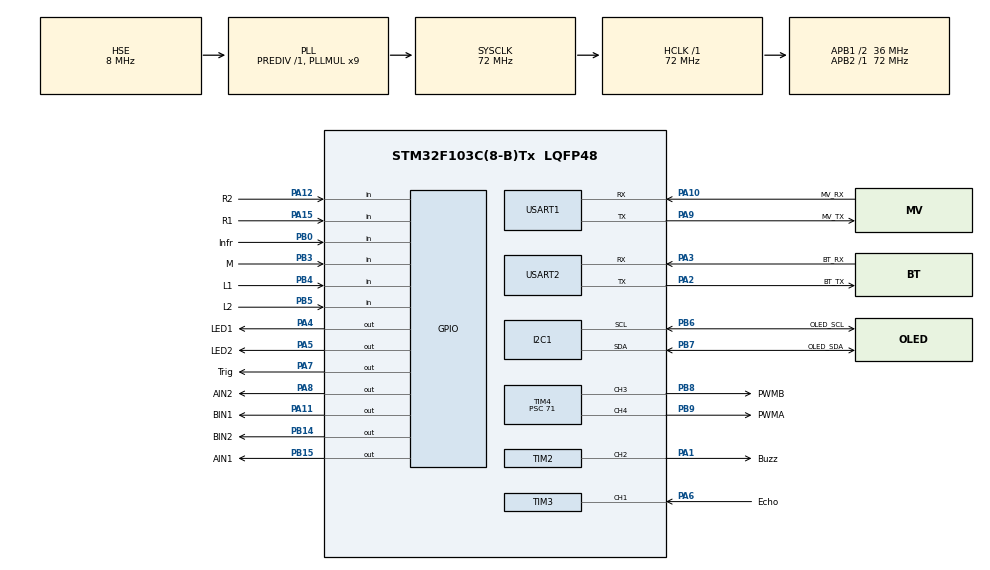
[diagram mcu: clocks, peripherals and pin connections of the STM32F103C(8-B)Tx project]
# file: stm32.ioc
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Dma.Request0=USART2_RX
Dma.Request1=USART2_TX
Dma.USART2_RX.0.Direction=DMA_PERIPH_TO_MEMORY
Dma.USART2_RX.0.Instance=DMA1_Channel6
Dma.USART2_RX.0.MemDataAlignment=DMA_MDATAALIGN_BYTE
Dma.USART2_RX.0.MemInc=DMA_MINC_ENABLE
Dma.USART2_RX.0.Mode=DMA_NORMAL
Dma.USART2_RX.0.PeriphDataAlignment=DMA_PDATAALIGN_BYTE
Dma.USART2_RX.0.PeriphInc=DMA_PINC_DISABLE
Dma.USART2_RX.0.Priority=DMA_PRIORITY_LOW
Dma.USART2_TX.1.Direction=DMA_MEMORY_TO_PERIPH
Dma.USART2_TX.1.Instance=DMA1_Channel7
Dma.USART2_TX.1.MemDataAlignment=DMA_MDATAALIGN_BYTE
Dma.USART2_TX.1.MemInc=DMA_MINC_ENABLE
Dma.USART2_TX.1.Mode=DMA_NORMAL
Dma.USART2_TX.1.PeriphDataAlignment=DMA_PDATAALIGN_BYTE
Dma.USART2_TX.1.PeriphInc=DMA_PINC_DISABLE
Dma.USART2_TX.1.Priority=DMA_PRIORITY_LOW
Mcu.Family=STM32F1
Mcu.Name=STM32F103C(8-B)Tx
Mcu.Package=LQFP48
NVIC.DMA1_Channel6_IRQn=true\:0\:0\:false\:false\:true\:false\:true\:true
NVIC.DMA1_Channel7_IRQn=true\:0\:0\:false\:false\:true\:false\:true\:true
NVIC.PriorityGroup=NVIC_PRIORITYGROUP_4
NVIC.TIM3_IRQn=true\:0\:0\:false\:false\:true\:true\:true\:true
NVIC.USART2_IRQn=true\:0\:0\:false\:false\:true\:false\:true\:true
PA1.GPIO_Label=Buzz
PA1.Signal=S_TIM2_CH2
PA10.GPIO_Label=MV_RX
PA10.Mode=Asynchronous
PA10.Signal=USART1_RX
PA11.GPIO_Label=BIN1
PA11.GPIO_PuPd=GPIO_PULLDOWN
PA11.Signal=GPIO_Output
PA12.GPIO_Label=R2
PA12.GPIO_PuPd=GPIO_PULLDOWN
PA12.Signal=GPIO_Input
PA13.Mode=Serial_Wire
PA13.Signal=SYS_JTMS-SWDIO
PA14.Mode=Serial_Wire
PA14.Signal=SYS_JTCK-SWCLK
PA15.GPIO_Label=R1
PA15.GPIO_PuPd=GPIO_PULLDOWN
PA15.Signal=GPIO_Input
PA2.GPIO_Label=BT_TX
PA2.Mode=Asynchronous
PA2.Signal=USART2_TX
PA3.GPIO_Label=BT_RX
PA3.Mode=Asynchronous
PA3.Signal=USART2_RX
PA4.GPIO_Label=LED1
PA4.GPIO_ModeDefaultOutputPP=GPIO_MODE_OUTPUT_PP
PA4.GPIO_PuPd=GPIO_PULLDOWN
PA4.Signal=GPIO_Output
PA5.GPIO_Label=LED2
PA5.GPIO_PuPd=GPIO_PULLDOWN
PA5.Signal=GPIO_Output
PA6.GPIO_Label=Echo
PA6.Signal=S_TIM3_CH1
PA7.GPIO_Label=Trig
PA7.GPIO_PuPd=GPIO_PULLUP
PA7.GPIO_Speed=GPIO_SPEED_FREQ_HIGH
PA7.Signal=GPIO_Output
PA8.GPIO_Label=AIN2
PA8.GPIO_PuPd=GPIO_PULLDOWN
PA8.Signal=GPIO_Output
PA9.GPIO_Label=MV_TX
PA9.Mode=Asynchronous
PA9.Signal=USART1_TX
PB0.GPIO_Label=Infr
PB0.GPIO_PuPd=GPIO_PULLUP
PB0.Signal=GPIO_Input
PB14.GPIO_Label=BIN2
PB14.GPIO_PuPd=GPIO_PULLDOWN
PB14.Signal=GPIO_Output
PB15.GPIO_Label=AIN1
PB15.GPIO_PuPd=GPIO_PULLDOWN
PB15.Signal=GPIO_Output
PB3.GPIO_Label=M
PB3.GPIO_PuPd=GPIO_PULLDOWN
PB3.Signal=GPIO_Input
PB4.GPIO_Label=L1
PB4.GPIO_PuPd=GPIO_PULLDOWN
PB4.Signal=GPIO_Input
PB5.GPIO_Label=L2
PB5.GPIO_PuPd=GPIO_PULLDOWN
PB5.Signal=GPIO_Input
PB6.GPIO_Label=OLED_SCL
PB6.Mode=I2C
PB6.Signal=I2C1_SCL
PB7.GPIO_Label=OLED_SDA
PB7.Mode=I2C
PB7.Signal=I2C1_SDA
PB8.GPIO_Label=PWMB
PB8.Signal=S_TIM4_CH3
PB9.GPIO_Label=PWMA
PB9.Signal=S_TIM4_CH4
PD0-OSC_IN.Mode=HSE-External-Oscillator
PD0-OSC_IN.Signal=RCC_OSC_IN
PD1-OSC_OUT.Mode=HSE-External-Oscillator
PD1-OSC_OUT.Signal=RCC_OSC_OUT
ProjectManager.HeapSize=0x200
ProjectManager.StackSize=0x400
ProjectManager.TargetToolchain=Makefile
RCC.AHBFreq_Value=72000000
RCC.APB1CLKDivider=RCC_HCLK_DIV2
RCC.APB1Freq_Value=36000000
RCC.APB1TimFreq_Value=72000000
RCC.APB2Freq_Value=72000000
RCC.APB2TimFreq_Value=72000000
RCC.HCLKFreq_Value=72000000
RCC.PLLMUL=RCC_PLL_MUL9
RCC.PLLSourceVirtual=RCC_PLLSOURCE_HSE
RCC.SYSCLKFreq_VALUE=72000000
RCC.SYSCLKSource=RCC_SYSCLKSOURCE_PLLCLK
RCC.USBFreq_Value=72000000
SH.S_TIM2_CH2.0=TIM2_CH2,PWM Generation2 CH2
SH.S_TIM3_CH1.0=TIM3_CH1,Input_Capture1_from_TI1
SH.S_TIM4_CH3.0=TIM4_CH3,PWM Generation3 CH3
SH.S_TIM4_CH4.0=TIM4_CH4,PWM Generation4 CH4
TIM2.AutoReloadPreload=TIM_AUTORELOAD_PRELOAD_ENABLE
TIM2.Channel-PWM\ Generation2\ CH2=TIM_CHANNEL_2
TIM2.Period=19999
TIM2.Prescaler=71
TIM3.AutoReloadPreload=TIM_AUTORELOAD_PRELOAD_ENABLE
TIM3.Channel-Input_Capture1_from_TI1=TIM_CHANNEL_1
TIM3.Prescaler=71
TIM4.AutoReloadPreload=TIM_AUTORELOAD_PRELOAD_ENABLE
TIM4.Channel-PWM\ Generation3\ CH3=TIM_CHANNEL_3
TIM4.Channel-PWM\ Generation4\ CH4=TIM_CHANNEL_4
TIM4.Period=19999
TIM4.Prescaler=71
USART1.VirtualMode=VM_ASYNC
USART2.VirtualMode=VM_ASYNC
board=custom

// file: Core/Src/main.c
/* USER CODE BEGIN Header */
/**
  ******************************************************************************
  * @file           : main.c
  * @brief          : Main program body
  ******************************************************************************
  * @attention
  *
  * Copyright (c) 2024 STMicroelectronics.
  * All rights reserved.
  *
  * This software is licensed under terms that can be found in the LICENSE file
  * in the root directory of this software component.
  * If no LICENSE file comes with this software, it is provided AS-IS.
  *
  ******************************************************************************
  */
/* USER CODE END Header */
#include "main.h"
#include "dma.h"
#include "i2c.h"
#include "tim.h"
#include "usart.h"
#include "gpio.h"

/* USER CODE BEGIN Includes */
#include "bsp.h"
/* USER CODE END Includes */

void SystemClock_Config(void);

int main(void)
{

  /* MCU Configuration--------------------------------------------------------*/

  /* Reset of all peripherals, Initializes the Flash interface and the Systick. */
  HAL_Init();

  /* Configure the system clock */
  SystemClock_Config();

  /* Initialize all configured peripherals */
  MX_GPIO_Init();
  MX_DMA_Init();
  MX_TIM3_Init();
  MX_USART1_UART_Init();
  MX_USART2_UART_Init();
  MX_I2C1_Init();
  MX_TIM2_Init();
  MX_TIM4_Init();

  /* Infinite loop */
  while (1)
  {

  }
}

void SystemClock_Config(void)
{
  RCC_OscInitTypeDef RCC_OscInitStruct = {0};
  RCC_ClkInitTypeDef RCC_ClkInitStruct = {0};

  /** Initializes the RCC Oscillators according to the specified parameters
  * in the RCC_OscInitTypeDef structure.
  */
  RCC_OscInitStruct.OscillatorType = RCC_OSCILLATORTYPE_HSE;
  RCC_OscInitStruct.HSEState = RCC_HSE_ON;
  RCC_OscInitStruct.HSEPredivValue = RCC_HSE_PREDIV_DIV1;
  RCC_OscInitStruct.HSIState = RCC_HSI_ON;
  RCC_OscInitStruct.PLL.PLLState = RCC_PLL_ON;
  RCC_OscInitStruct.PLL.PLLSource = RCC_PLLSOURCE_HSE;
  RCC_OscInitStruct.PLL.PLLMUL = RCC_PLL_MUL9;
  if (HAL_RCC_OscConfig(&RCC_OscInitStruct) != HAL_OK)
  {
    Error_Handler();
  }

  /** Initializes the CPU, AHB and APB buses clocks
  */
  RCC_ClkInitStruct.ClockType = RCC_CLOCKTYPE_HCLK|RCC_CLOCKTYPE_SYSCLK
                              |RCC_CLOCKTYPE_PCLK1|RCC_CLOCKTYPE_PCLK2;
  RCC_ClkInitStruct.SYSCLKSource = RCC_SYSCLKSOURCE_PLLCLK;
  RCC_ClkInitStruct.AHBCLKDivider = RCC_SYSCLK_DIV1;
  RCC_ClkInitStruct.APB1CLKDivider = RCC_HCLK_DIV2;
  RCC_ClkInitStruct.APB2CLKDivider = RCC_HCLK_DIV1;

  if (HAL_RCC_ClockConfig(&RCC_ClkInitStruct, FLASH_LATENCY_2) != HAL_OK)
  {
    Error_Handler();
  }
}

void Error_Handler(void)
{
  __disable_irq();
  while (1)
  {
  }
}
